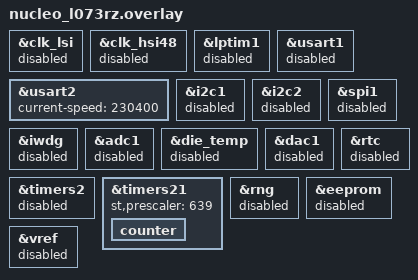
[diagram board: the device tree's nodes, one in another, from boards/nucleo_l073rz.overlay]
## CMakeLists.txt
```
# SPDX-License-Identifier: Apache-2.0

cmake_minimum_required(VERSION 3.20.0)

find_package(Zephyr REQUIRED HINTS $ENV{ZEPHYR_BASE})
project(minimal)

target_sources(app PRIVATE src/main.c src/fxp16.c src/mandelbrot.c)
```

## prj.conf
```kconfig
CONFIG_MYOS=y
CONFIG_MYOS_STACK_SIZE=2048
CONFIG_MYOS_THREAD_PRIORITY=7

CONFIG_MYOS_DEBUG=y
CONFIG_MYOS_DEBUG_RTIMER=y
CONFIG_MYOS_DEBUG_TIMESTAMP=y




CONFIG_LOG=y
CONFIG_LOG_DEFAULT_LEVEL=3
CONFIG_LOG_MODE_IMMEDIATE=y

CONFIG_COUNTER=y
CONFIG_COUNTER_TIMER_STM32=y
```

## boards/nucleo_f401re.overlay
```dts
&usart2 {
	current-speed = <230400>;
};



&timers9 {
    status = "okay";
    st,prescaler = <1679>;    /* 84 MHz / (1679 + 1) = 50 kHz */

    counter {
        status = "okay";
    };
};
```

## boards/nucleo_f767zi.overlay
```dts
&usart3 {
	current-speed = <230400>;
};

&timers9 {
    status = "okay";
    st,prescaler = <4319>;    /* 216 MHz / (4319+1) = 50 kHz */

    counter {
        status = "okay";
    };
};
```

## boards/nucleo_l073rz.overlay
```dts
&clk_lsi {
	status = "disabled";
};

&clk_hsi48 {
	status = "disabled";
};


stm32_lp_tick_source: &lptim1 {
	status = "disabled";
};

&usart1 {
	status = "disabled";
};

&usart2 {
	current-speed = <230400>;
};

&i2c1 {
	status = "disabled";
};

&i2c2 {
	status = "disabled";
};

&spi1 {
	status = "disabled";
};

&iwdg {
	status = "disabled";
};

&adc1 {
	status = "disabled";
};

&die_temp {
	status = "disabled";
};

&dac1 {
    status = "disabled";
};

&timers2 {
	status = "disabled";
};


&timers21 {
    status = "okay";
    st,prescaler = <639>;   /* 32 MHz / (639+1) = 50 kHz */

    counter {
        status = "okay";
    };
};

&rtc {
	status = "disabled";
};

&rng {
	status = "disabled";
};

&eeprom {
	status = "disabled";
};

&vref {
	status = "disabled";
};
```

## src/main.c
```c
/*
 * Copyright (c) 2025 Marco Bacchi
 */


#include <zephyr/kernel.h>
#include <zephyr/init.h>
#include <zephyr/logging/log.h>

#include "myos.h"
#include "mandelbrot.h"

LOG_MODULE_REGISTER(myos, LOG_LEVEL_INF);

static int my_early_init(void)
{
	printk("Early init \n");
	return 0;
}

SYS_INIT(my_early_init, POST_KERNEL, 50);

void rtimer_callback(void* data)
{
	static int cnt = 0;

	if( cnt++ < 10 )
	{
		rtimer_t* rt = (rtimer_t*)data;	
		rtimer_reset(rt);
		rtimer_lock();
	}

	LOG_INF("Rtimer callback fired %d",cnt);
}


PROCESS(counter,counter);
PROCESS_THREAD(counter)
{
	static etimer_t et;
	static rtimer_t rt;

	static uint32_t cnt = 0;

    PROCESS_BEGIN();

	LOG_INF("Started counter process");

	process_start(&mandelbrot,NULL);

	PROCESS_RTIMER_ACQUIRE();
	rtimer_start(&rt, RTIMER_TICKS_PER_SEC/4 , rtimer_callback, &rt);
	PROCESS_RTIMER_JOIN();
	
	while(1)
	{
		PROCESS_SLEEP(&et,TIMESTAMP_TICKS_PER_SEC);
	}


	PROCESS_END();
}


void myos_scheduler(void)
{

	LOG_INF("MyOS thread running");
	myos_init();

	process_start(&counter,NULL);

	for(;;)
	{
		process_run();
	}
}
 

K_THREAD_DEFINE(
	myos_scheduler_id, 
	CONFIG_MYOS_STACK_SIZE, 
	myos_scheduler, 
	NULL, 
	NULL, 
	NULL, 		
	CONFIG_MYOS_THREAD_PRIORITY,
	0, 
	0);
```

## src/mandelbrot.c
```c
#include "mandelbrot.h"
#include "fxp16.h"

#define XRES 80
#define YRES 40
#define MAGNIFY 1

#define FP_0_7      0x00b3
#define FP_0_5      0x0080
#define FP_3_0      0x0300
#define FP_2_0      0x0200
#define FP_100_0    0x6400

#define FP_FRAC     8
    
PROCESS(mandelbrot,mandelbrot);
PROCESS_THREAD(mandelbrot)
{
    static fxp16_t   x,tmp1,tmp2,y,cx,cy;
    static uint8_t  hx,hy,iteration;
    static uint8_t itermax;                 /* how many iterations to do	*/
    
    const char *cols = "`^\",:;Il!i~+_-?][}{1)(|\\/tfjrxnuvczXYUJCLQ0OZmwqpdbkhao*#MW&8%B@$";
    
    PROCESS_BEGIN();

    itermax = strlen(cols)-1;

    for(;;)
    {
        for (hy=0; hy < YRES; hy++)  
        {
            for (hx=0; hx < XRES; hx++)  
            {
                //cx = (((float)hx)/((float)hxres)-0.5)/magnify*3.0-0.7;
                tmp1 = fxp16_int2fp(hx,FP_FRAC);
                tmp2 = fxp16_int2fp(XRES,FP_FRAC);
                cx = fxp16_div(tmp1,FP_FRAC,tmp2,FP_FRAC);
                cx = fxp16_sub(cx,FP_0_5);
                tmp1 = fxp16_int2fp(MAGNIFY,FP_FRAC);
                cx = fxp16_div(cx,FP_FRAC,tmp1,FP_FRAC);
                cx = fxp16_mult(cx,FP_FRAC,FP_3_0,FP_FRAC);
                cx = fxp16_sub(cx,FP_0_7);


                
                
                //cy = (((float)hy)/((float)hyres)-0.5)/magnify*3.0;                  
                tmp1 = fxp16_int2fp(hy,FP_FRAC);
                tmp2 = fxp16_int2fp(YRES,FP_FRAC);
                cy = fxp16_div(tmp1,FP_FRAC,tmp2,FP_FRAC);
                cy = fxp16_sub(cy,FP_0_5);
                tmp1 = fxp16_int2fp(MAGNIFY,FP_FRAC);
                cy = fxp16_div(cy,FP_FRAC,tmp1,FP_FRAC);
                cy = fxp16_mult(cy,FP_FRAC,FP_3_0,FP_FRAC);
     
                
                x = y = 0;              

                for (iteration = 0;iteration < itermax; iteration++)  
                {      
                    // xx = x*x-y*y+cx;
                    tmp1 = fxp16_mult(x,FP_FRAC,x,FP_FRAC);
                    tmp2 = fxp16_mult(y,FP_FRAC,y,FP_FRAC);
                    tmp1 = fxp16_sub(tmp1,tmp2);                       
                    tmp1 = fxp16_add(tmp1,cx);

                    
                    // y = 2.0*x*y+cy;
                    y = fxp16_mult(x,FP_FRAC,y,FP_FRAC);
                    y = fxp16_mult(FP_2_0,FP_FRAC,y,FP_FRAC);
                    y = fxp16_add(y,cy);
                    
                    x = tmp1;

                    
                    tmp1 = fxp16_mult(x,FP_FRAC,x,FP_FRAC);
                    tmp2 = fxp16_mult(y,FP_FRAC,y,FP_FRAC);
                    
                    
                    
                    if (fxp16_add(tmp1,tmp2) > FP_100_0)
                    {
                        break;    // check if this works with protothreads!              
                    }
                    
                    PROCESS_YIELD();
                    
                }
                
                
                putchar(cols[iteration]);                
            }


            putchar('\n');
        }
    }   
    
    PROCESS_END();
}
```

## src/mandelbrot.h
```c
/* 
 * File:   mandelbrot.h
 * Author: marco@bacchi.at
 *
 * Created on December 17, 2021, 9:32 AM
 */

#ifndef MANDELBROT_H
#define	MANDELBROT_H

#include "myos.h"

EXTERN_PROCESS(mandelbrot);

#endif	/* MANDELBROT_H */
```
